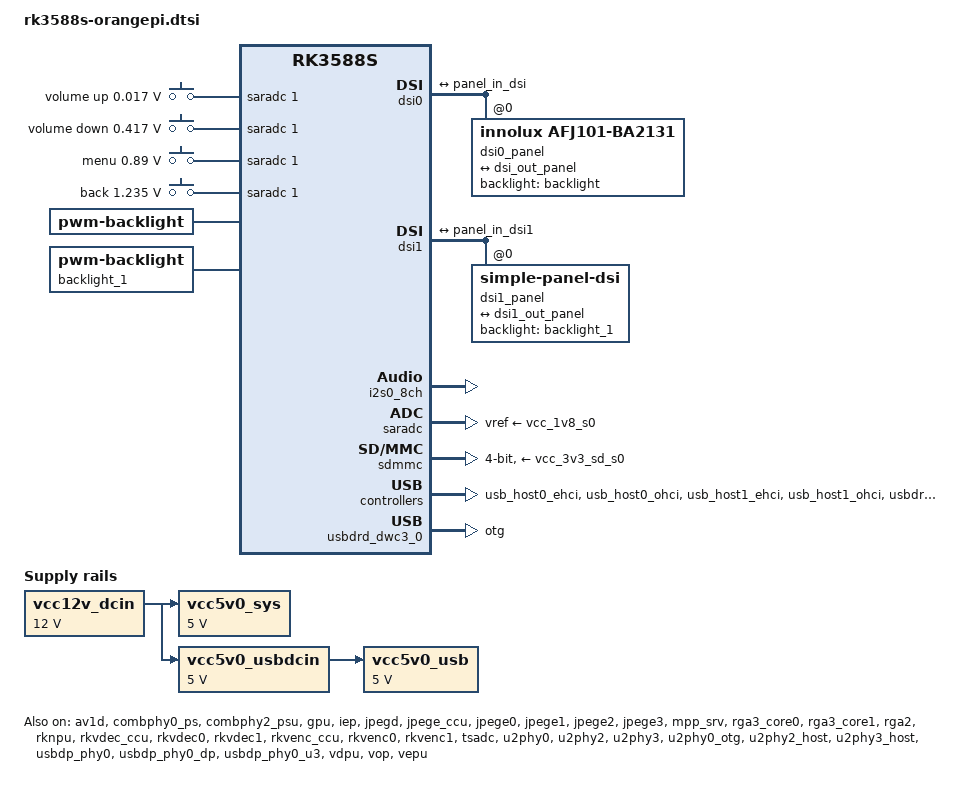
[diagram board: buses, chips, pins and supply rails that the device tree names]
// SPDX-License-Identifier: (GPL-2.0+ OR MIT)
/*
 * Copyright (c) 2021 Rockchip Electronics Co., Ltd.
 *
 */

#include <dt-bindings/gpio/gpio.h>
#include <dt-bindings/pwm/pwm.h>
#include <dt-bindings/pinctrl/rockchip.h>
#include <dt-bindings/input/rk-input.h>
#include <dt-bindings/display/drm_mipi_dsi.h>
#include <dt-bindings/display/rockchip_vop.h>
#include <dt-bindings/sensor-dev.h>

/ {
	adc_keys: adc-keys {
		compatible = "adc-keys";
		io-channels = <&saradc 1>;
		io-channel-names = "buttons";
		keyup-threshold-microvolt = <1800000>;
		poll-interval = <100>;

		vol-up-key {
			label = "volume up";
			linux,code = <KEY_VOLUMEUP>;
			press-threshold-microvolt = <17000>;
		};

		vol-down-key {
			label = "volume down";
			linux,code = <KEY_VOLUMEDOWN>;
			press-threshold-microvolt = <417000>;
		};

		menu-key {
			label = "menu";
			linux,code = <KEY_MENU>;
			press-threshold-microvolt = <890000>;
		};

		back-key {
			label = "back";
			linux,code = <KEY_BACK>;
			press-threshold-microvolt = <1235000>;
		};
	};

	backlight: backlight {
		compatible = "pwm-backlight";
		brightness-levels = <
				0	20	20	21	21	22	22	23
			 23	24	24	25	25	26	26	27
			 27	28	28	29	29	30	30	31
			 31	32	32	33	33	34	34	35
			 35	36	36	37	37	38	38	39
			 40	41	42	43	44	45	46	47
			 48	49	50	51	52	53	54	55
			 56	57	58	59	60	61	62	63
			 64	65	66	67	68	69	70	71
			 72	73	74	75	76	77	78	79
			 80	81	82	83	84	85	86	87
			 88	89	90	91	92	93	94	95
			 96	97	98	99 100 101 102 103
			104 105 106 107 108 109 110 111
			112 113 114 115 116 117 118 119
			120 121 122 123 124 125 126 127
			128 129 130 131 132 133 134 135
			136 137 138 139 140 141 142 143
			144 145 146 147 148 149 150 151
			152 153 154 155 156 157 158 159
			160 161 162 163 164 165 166 167
			168 169 170 171 172 173 174 175
			176 177 178 179 180 181 182 183
			184 185 186 187 188 189 190 191
			192 193 194 195 196 197 198 199
			200 201 202 203 204 205 206 207
			208 209 210 211 212 213 214 215
			216 217 218 219 220 221 222 223
			224 225 226 227 228 229 230 231
			232 233 234 235 236 237 238 239
			240 241 242 243 244 245 246 247
			248 249 250 251 252 253 254 255
		>;
		default-brightness-level = <200>;
	};

	backlight_1: backlight_1 {
		compatible = "pwm-backlight";
		brightness-levels = <
				0	20	20	21	21	22	22	23
			 23	24	24	25	25	26	26	27
			 27	28	28	29	29	30	30	31
			 31	32	32	33	33	34	34	35
			 35	36	36	37	37	38	38	39
			 40	41	42	43	44	45	46	47
			 48	49	50	51	52	53	54	55
			 56	57	58	59	60	61	62	63
			 64	65	66	67	68	69	70	71
			 72	73	74	75	76	77	78	79
			 80	81	82	83	84	85	86	87
			 88	89	90	91	92	93	94	95
			 96	97	98	99 100 101 102 103
			104 105 106 107 108 109 110 111
			112 113 114 115 116 117 118 119
			120 121 122 123 124 125 126 127
			128 129 130 131 132 133 134 135
			136 137 138 139 140 141 142 143
			144 145 146 147 148 149 150 151
			152 153 154 155 156 157 158 159
			160 161 162 163 164 165 166 167
			168 169 170 171 172 173 174 175
			176 177 178 179 180 181 182 183
			184 185 186 187 188 189 190 191
			192 193 194 195 196 197 198 199
			200 201 202 203 204 205 206 207
			208 209 210 211 212 213 214 215
			216 217 218 219 220 221 222 223
			224 225 226 227 228 229 230 231
			232 233 234 235 236 237 238 239
			240 241 242 243 244 245 246 247
			248 249 250 251 252 253 254 255
		>;
		default-brightness-level = <200>;
	};

	dp0_sound: dp0-sound {
		status = "disabled";
		compatible = "rockchip,hdmi";
		rockchip,card-name= "rockchip-dp0";
		rockchip,mclk-fs = <512>;
		rockchip,cpu = <&spdif_tx2>;
		rockchip,codec = <&dp0 1>;
		rockchip,jack-det;
	};

	hdmi0_sound: hdmi0-sound {
		status = "disabled";
		compatible = "rockchip,hdmi";
		rockchip,mclk-fs = <128>;
		rockchip,card-name = "rockchip-hdmi0";
		rockchip,cpu = <&i2s5_8ch>;
		rockchip,codec = <&hdmi0>;
		rockchip,jack-det;
	};

	spdif_tx1_dc: spdif-tx1-dc {
		status = "disabled";
		compatible = "linux,spdif-dit";
		#sound-dai-cells = <0>;
	};

	spdif_tx1_sound: spdif-tx1-sound {
		status = "disabled";
		compatible = "simple-audio-card";
		simple-audio-card,name = "rockchip,spdif-tx1";
		simple-audio-card,cpu {
			sound-dai = <&spdif_tx1>;
		};
		simple-audio-card,codec {
			sound-dai = <&spdif_tx1_dc>;
		};
	};

	test-power {
		status = "okay";
	};

	vcc12v_dcin: vcc12v-dcin {
		compatible = "regulator-fixed";
		regulator-name = "vcc12v_dcin";
		regulator-always-on;
		regulator-boot-on;
		regulator-min-microvolt = <12000000>;
		regulator-max-microvolt = <12000000>;
	};

	vcc5v0_sys: vcc5v0-sys {
		compatible = "regulator-fixed";
		regulator-name = "vcc5v0_sys";
		regulator-always-on;
		regulator-boot-on;
		regulator-min-microvolt = <5000000>;
		regulator-max-microvolt = <5000000>;
		vin-supply = <&vcc12v_dcin>;
	};

	vcc5v0_usbdcin: vcc5v0-usbdcin {
		compatible = "regulator-fixed";
		regulator-name = "vcc5v0_usbdcin";
		regulator-always-on;
		regulator-boot-on;
		regulator-min-microvolt = <5000000>;
		regulator-max-microvolt = <5000000>;
		vin-supply = <&vcc12v_dcin>;
	};

	vcc5v0_usb: vcc5v0-usb {
		compatible = "regulator-fixed";
		regulator-name = "vcc5v0_usb";
		regulator-always-on;
		regulator-boot-on;
		regulator-min-microvolt = <5000000>;
		regulator-max-microvolt = <5000000>;
		vin-supply = <&vcc5v0_usbdcin>;
	};
};

&av1d {
	status = "okay";
};

&av1d_mmu {
	status = "okay";
};

&combphy0_ps {
	status = "okay";
};

&combphy2_psu {
	status = "okay";
};

&cpu_l0 {
	cpu-supply = <&vdd_cpu_lit_s0>;
	mem-supply = <&vdd_cpu_lit_mem_s0>;
};

&cpu_b0 {
	cpu-supply = <&vdd_cpu_big0_s0>;
	mem-supply = <&vdd_cpu_big0_mem_s0>;
};

&cpu_b2 {
	cpu-supply = <&vdd_cpu_big1_s0>;
	mem-supply = <&vdd_cpu_big1_mem_s0>;
};

&dsi0 {
	status = "okay";
	//rockchip,lane-rate = <1000>;
	dsi0_panel: panel@0 {
		status = "okay";
		compatible = "innolux,afj101-ba2131";
		reg = <0>;
		backlight = <&backlight>;

		ports {
			#address-cells = <1>;
			#size-cells = <0>;

			port@0 {
				reg = <0>;
				panel_in_dsi: endpoint {
					remote-endpoint = <&dsi_out_panel>;
				};
			};
		};
	};

	ports {
		#address-cells = <1>;
		#size-cells = <0>;

		port@1 {
			reg = <1>;
			dsi_out_panel: endpoint {
				remote-endpoint = <&panel_in_dsi>;
			};
		};
	};

};

&dsi1 {
	status = "okay";
	dsi1_panel: panel@0 {
		status = "okay";
		reg = <0>;
		backlight = <&backlight_1>;
		compatible = "simple-panel-dsi";
		prepare-delay-ms = <20>;
		reset-delay-ms = <50>;
		init-delay-ms = <50>;
		enable-delay-ms = <100>;
		unprepare-delay-ms = <30>;
		disable-delay-ms = <30>;
		dsi,flags = <(MIPI_DSI_MODE_VIDEO | MIPI_DSI_MODE_VIDEO_BURST |
								 MIPI_DSI_MODE_LPM | MIPI_DSI_MODE_EOT_PACKET)>;
		dsi,format = <MIPI_DSI_FMT_RGB888>;
		dsi,lanes	= <4>;

		panel-init-sequence = [
			39 00 04 FF 98 81 03
			15 00 02 01 00
			15 00 02 02 00
			15 00 02 03 73
			15 00 02 04 00
			15 00 02 05 00
			15 00 02 06 0A
			15 00 02 07 00
			15 00 02 08 00
			15 00 02 09 01
			15 00 02 0A 00
			15 00 02 0B 00
			15 00 02 0C 01
			15 00 02 0D 00
			15 00 02 0E 00
			15 00 02 0F 1D
			15 00 02 10 1D
			15 00 02 11 00
			15 00 02 12 00
			15 00 02 13 00
			15 00 02 14 00
			15 00 02 15 00
			15 00 02 16 00
			15 00 02 17 00
			15 00 02 18 00
			15 00 02 19 00
			15 00 02 1A 00
			15 00 02 1B 00
			15 00 02 1C 00
			15 00 02 1D 00
			15 00 02 1E 40
			15 00 02 1F 80
			15 00 02 20 06
			15 00 02 21 02
			15 00 02 22 00
			15 00 02 23 00
			15 00 02 24 00
			15 00 02 25 00
			15 00 02 26 00
			15 00 02 27 00
			15 00 02 28 33
			15 00 02 29 03
			15 00 02 2A 00
			15 00 02 2B 00
			15 00 02 2C 00
			15 00 02 2D 00
			15 00 02 2E 00
			15 00 02 2F 00
			15 00 02 30 00
			15 00 02 31 00
			15 00 02 32 00
			15 00 02 33 00
			15 00 02 34 04
			15 00 02 35 00
			15 00 02 36 00
			15 00 02 37 00
			15 00 02 38 3C
			15 00 02 39 35
			15 00 02 3A 01
			15 00 02 3B 40
			15 00 02 3C 00
			15 00 02 3D 01
			15 00 02 3E 00
			15 00 02 3F 00
			15 00 02 40 00
			15 00 02 41 88
			15 00 02 42 00
			15 00 02 43 00
			15 00 02 44 1F
			15 00 02 50 01
			15 00 02 51 23
			15 00 02 52 45
			15 00 02 53 67
			15 00 02 54 89
			15 00 02 55 AB
			15 00 02 56 01
			15 00 02 57 23
			15 00 02 58 45
			15 00 02 59 67
			15 00 02 5A 89
			15 00 02 5B AB
			15 00 02 5C CD
			15 00 02 5D EF
			15 00 02 5E 11
			15 00 02 5F 01
			15 00 02 60 00
			15 00 02 61 15
			15 00 02 62 14
			15 00 02 63 0E
			15 00 02 64 0F
			15 00 02 65 0C
			15 00 02 66 0D
			15 00 02 67 06
			15 00 02 68 02
			15 00 02 69 07
			15 00 02 6A 02
			15 00 02 6B 02
			15 00 02 6C 02
			15 00 02 6D 02
			15 00 02 6E 02
			15 00 02 6F 02
			15 00 02 70 02
			15 00 02 71 02
			15 00 02 72 02
			15 00 02 73 02
			15 00 02 74 02
			15 00 02 75 01
			15 00 02 76 00
			15 00 02 77 14
			15 00 02 78 15
			15 00 02 79 0E
			15 00 02 7A 0F
			15 00 02 7B 0C
			15 00 02 7C 0D
			15 00 02 7D 06
			15 00 02 7E 02
			15 00 02 7F 07
			15 00 02 80 02
			15 00 02 81 02
			15 00 02 82 02
			15 00 02 83 02
			15 00 02 84 02
			15 00 02 85 02
			15 00 02 86 02
			15 00 02 87 02
			15 00 02 88 02
			15 00 02 89 02
			15 00 02 8A 02
			39 00 04 FF 98 81 04
			15 00 02 70 00
			15 00 02 71 00
			15 00 02 82 0F 
			15 00 02 84 0F 
			15 00 02 85 0D 
			15 00 02 32 AC
			15 00 02 8C 80
			15 00 02 3C F5
			15 00 02 B5 07 
			15 00 02 31 45 
			15 00 02 3A 24 
			15 00 02 88 33 
			39 00 04 FF 98 81 01
			15 00 02 22 09 
			15 00 02 31 00 
			15 00 02 53 8A 
			15 00 02 55 A2 
			15 00 02 50 81 
			15 00 02 51 85 
			15 00 02 62 0D
			39 00 04 FF 98 81 01
			15 00 02 A0 00
			15 00 02 A1 1A
			15 00 02 A2 28
			15 00 02 A3 13
			15 00 02 A4 16
			15 00 02 A5 29
			15 00 02 A6 1D
			15 00 02 A7 1E
			15 00 02 A8 84
			15 00 02 A9 1C
			15 00 02 AA 28
			15 00 02 AB 75
			15 00 02 AC 1A
			15 00 02 AD 19
			15 00 02 AE 4D
			15 00 02 AF 22
			15 00 02 B0 28
			15 00 02 B1 54
			15 00 02 B2 66
			15 00 02 B3 39
			15 00 02 C0 00
			15 00 02 C1 1A
			15 00 02 C2 28
			15 00 02 C3 13
			15 00 02 C4 16
			15 00 02 C5 29
			15 00 02 C6 1D
			15 00 02 C7 1E
			15 00 02 C8 84
			15 00 02 C9 1C
			15 00 02 CA 28
			15 00 02 CB 75
			15 00 02 CC 1A
			15 00 02 CD 19
			15 00 02 CE 4D
			15 00 02 CF 22
			15 00 02 D0 28
			15 00 02 D1 54
			15 00 02 D2 66
			15 00 02 D3 39
			39 00 04 FF 98 81 00
			15 00 02 35 00
			15 00 02 36 03
			15 FF 01 11
			15 FF 01 29
		];

		panel-exit-sequence = [
			05 00 01 28
			05 78 01 10
		];

		disp_timings0: display-timings {
			native-mode = <&dsi1_timing0>;
			dsi1_timing0: timing0 {
				clock-frequency = <52000000>; 
					hactive = <1024>;
					vactive = <600>;
					hback-porch = <150>;
					hfront-porch = <150>;
					vback-porch = <10>;
					vfront-porch = <10>;
					hsync-len = <30>;
					vsync-len = <20>;
					hsync-active = <0>;
					vsync-active = <0>;
					de-active = <0>;
					pixelclk-active = <0>;
					swap-rb = <0>;
					swap-rg = <0>;
					swap-gb = <0>;
			};
		};

		ports {
			#address-cells = <1>;
			#size-cells = <0>;

			port@0 {
				reg = <0>;
				panel_in_dsi1: endpoint {
					remote-endpoint = <&dsi1_out_panel>;
				};
			};
		};
	};

	ports {
		#address-cells = <1>;
		#size-cells = <0>;

		port@1 {
			reg = <1>;
			dsi1_out_panel: endpoint {
				remote-endpoint = <&panel_in_dsi1>;
			};
		};
	};

};

&gpu {
	mali-supply = <&vdd_gpu_s0>;
	mem-supply = <&vdd_gpu_mem_s0>;
	status = "okay";
};

&i2s0_8ch {
	status = "okay";
	pinctrl-0 = <&i2s0_lrck
				 &i2s0_sclk
				 &i2s0_sdi0
				 &i2s0_sdo0>;
};

&iep {
	status = "okay";
};

&iep_mmu {
	status = "okay";
};

&jpegd {
	status = "okay";
};

&jpegd_mmu {
	status = "okay";
};

&jpege_ccu {
	status = "okay";
};

&jpege0 {
	status = "okay";
};

&jpege0_mmu {
	status = "okay";
};

&jpege1 {
	status = "okay";
};

&jpege1_mmu {
	status = "okay";
};

&jpege2 {
	status = "okay";
};

&jpege2_mmu {
	status = "okay";
};

&jpege3 {
	status = "okay";
};

&jpege3_mmu {
	status = "okay";
};

&mpp_srv {
	status = "okay";
};

&rga3_core0 {
	status = "okay";
};

&rga3_0_mmu {
	status = "okay";
};

&rga3_core1 {
	status = "okay";
};

&rga3_1_mmu {
	status = "okay";
};

&rga2 {
	status = "okay";
};

&rknpu {
	rknpu-supply = <&vdd_npu_s0>;
	mem-supply = <&vdd_npu_mem_s0>;
	status = "okay";
};

&rknpu_mmu {
	status = "okay";
};

&rkvdec_ccu {
	status = "okay";
};

&rkvdec0 {
	status = "okay";
};

&rkvdec0_mmu {
	status = "okay";
};

&rkvdec1 {
	status = "okay";
};

&rkvdec1_mmu {
	status = "okay";
};

&rkvenc_ccu {
	status = "okay";
};

&rkvenc0 {
	status = "okay";
};

&rkvenc0_mmu {
	status = "okay";
};

&rkvenc1 {
	status = "okay";
};

&rkvenc1_mmu {
	status = "okay";
};

&rockchip_suspend {
	status = "okay";
	rockchip,sleep-debug-en = <1>;
};

&saradc {
	status = "okay";
	vref-supply = <&vcc_1v8_s0>;
};

&sdhci {
	bus-width = <8>;
	no-sdio;
	no-sd;
	non-removable;
	max-frequency = <200000000>;
	mmc-hs400-1_8v;
	mmc-hs400-enhanced-strobe;
	status = "disabled";
};

&sdmmc {
	max-frequency = <150000000>;
	no-sdio;
	no-mmc;
	bus-width = <4>;
	cap-mmc-highspeed;
	cap-sd-highspeed;
	disable-wp;
	sd-uhs-sdr104;
	vmmc-supply = <&vcc_3v3_sd_s0>;
	vqmmc-supply = <&vccio_sd_s0>;
	status = "okay";
};

&tsadc {
	status = "okay";
};

&u2phy0 {
	status = "okay";
};

&u2phy2 {
	status = "okay";
};

&u2phy3 {
	status = "okay";
};

&u2phy0_otg {
	status = "okay";
};

&u2phy2_host {
	status = "okay";
};

&u2phy3_host {
	status = "okay";
};

&usb_host0_ehci {
	status = "okay";
};

&usb_host0_ohci {
	status = "okay";
};

&usb_host1_ehci {
	status = "okay";
};

&usb_host1_ohci {
	status = "okay";
};

&usbdp_phy0 {
	status = "okay";
};

&usbdp_phy0_dp {
	status = "okay";
};

&usbdp_phy0_u3 {
	status = "okay";
};

&usbdrd3_0 {
	status = "okay";
};

&usbdrd_dwc3_0 {
	dr_mode = "otg";
	status = "okay";
};

&usbhost3_0 {
	status = "okay";
};

&usbhost_dwc3_0 {
	status = "okay";
};

&vdpu {
	status = "okay";
};

&vdpu_mmu {
	status = "okay";
};

&vop {
	status = "okay";
	assigned-clocks = <&cru ACLK_VOP>;
	assigned-clock-rates = <800000000>;
};

&vop_mmu {
	status = "okay";
};

&vepu {
	status = "okay";
};

/* vp0 & vp1 splice for 8K output */
&vp0 {
	rockchip,plane-mask = <(1 << ROCKCHIP_VOP2_CLUSTER0 | 1 << ROCKCHIP_VOP2_ESMART0)>;
	rockchip,primary-plane = <ROCKCHIP_VOP2_ESMART0>;
};

&vp1 {
	rockchip,plane-mask = <(1 << ROCKCHIP_VOP2_CLUSTER1 | 1 << ROCKCHIP_VOP2_ESMART1)>;
	rockchip,primary-plane = <ROCKCHIP_VOP2_ESMART1>;
};

&vp2 {
	rockchip,plane-mask = <(1 << ROCKCHIP_VOP2_CLUSTER2 | 1 << ROCKCHIP_VOP2_ESMART2)>;
	rockchip,primary-plane = <ROCKCHIP_VOP2_ESMART2>;
};

&vp3 {
	rockchip,plane-mask = <(1 << ROCKCHIP_VOP2_CLUSTER3 | 1 << ROCKCHIP_VOP2_ESMART3)>;
	rockchip,primary-plane = <ROCKCHIP_VOP2_ESMART3>;
};

